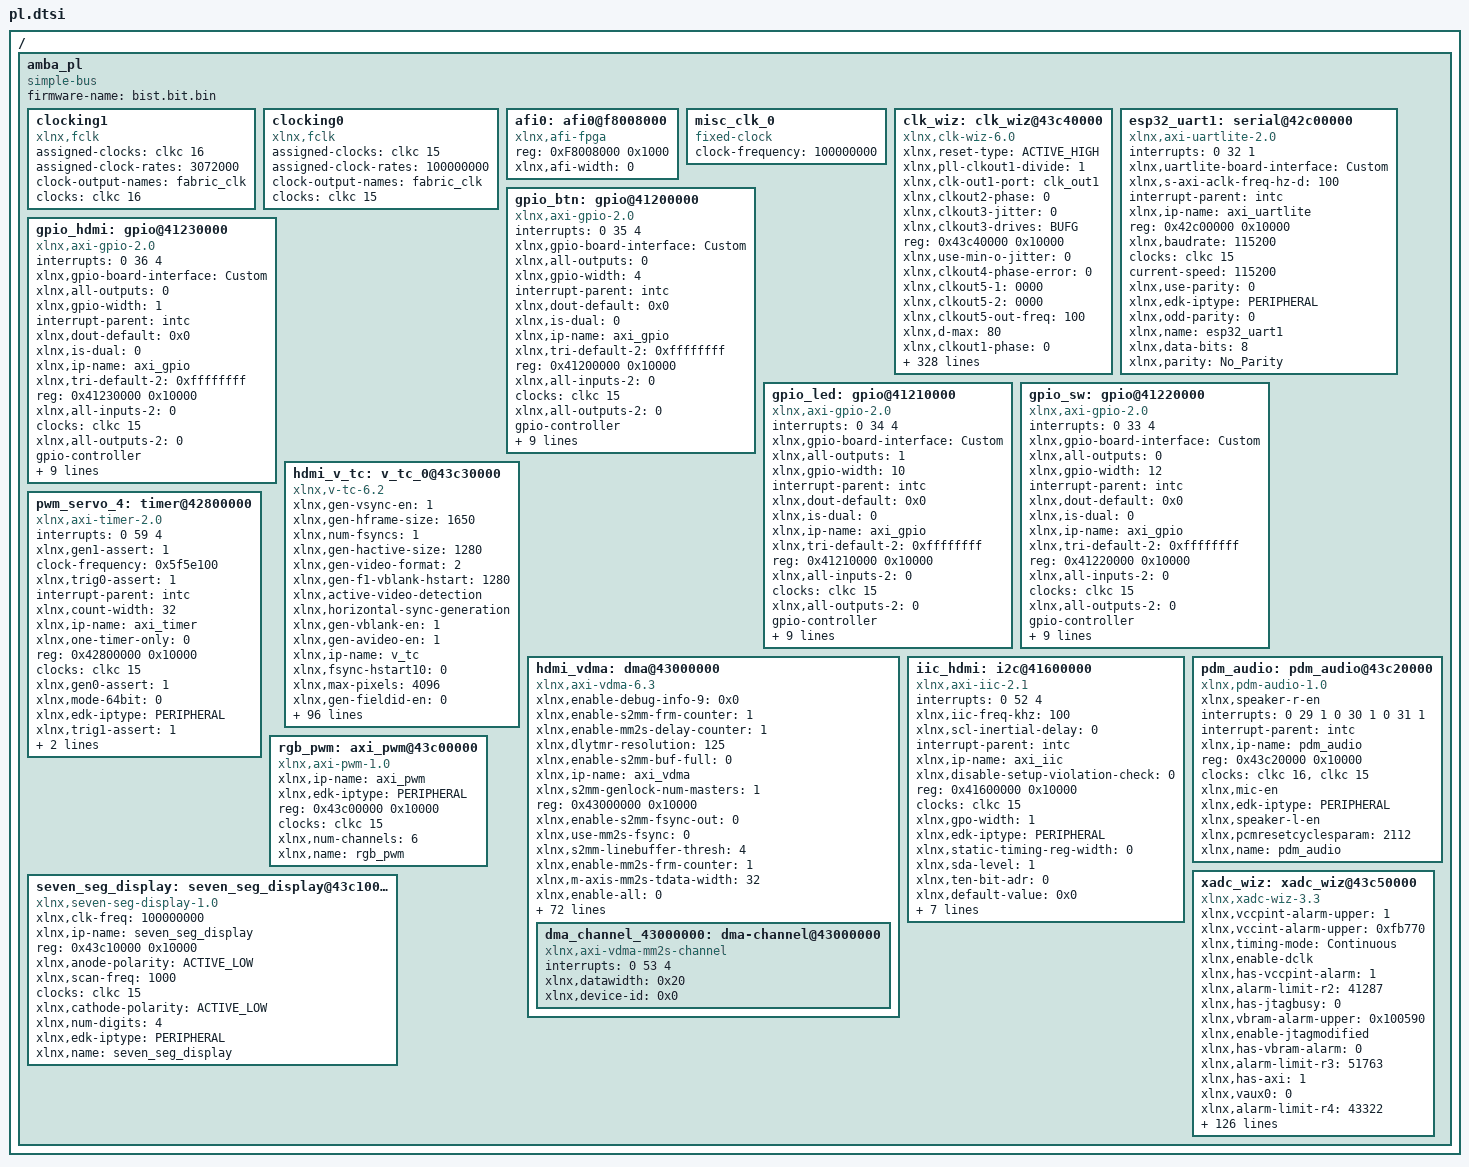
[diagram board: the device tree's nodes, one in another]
/ {
	amba_pl: amba_pl {
		ranges;
		compatible = "simple-bus";
		#address-cells = <1>;
		#size-cells = <1>;
		firmware-name = "bist.bit.bin";
		clocking1: clocking1 {
			compatible = "xlnx,fclk";
			assigned-clocks = <&clkc 16>;
			assigned-clock-rates = <3072000>;
			#clock-cells = <0>;
			clock-output-names = "fabric_clk";
			clocks = <&clkc 16>;
		};
		clocking0: clocking0 {
			compatible = "xlnx,fclk";
			assigned-clocks = <&clkc 15>;
			assigned-clock-rates = <100000000>;
			#clock-cells = <0>;
			clock-output-names = "fabric_clk";
			clocks = <&clkc 15>;
		};
		afi0: afi0@f8008000 {
			status = "okay";
			compatible = "xlnx,afi-fpga";
			#address-cells = <1>;
			reg = <0xF8008000 0x1000>;
			#size-cells = <0>;
			xlnx,afi-width = <0>;
		};
		misc_clk_0: misc_clk_0 {
			compatible = "fixed-clock";
			clock-frequency = <100000000>;
			#clock-cells = <0>;
		};
		clk_wiz: clk_wiz@43c40000 {
			xlnx,reset-type = "ACTIVE_HIGH";
			xlnx,pll-clkout1-divide = <1>;
			xlnx,clk-out1-port = "clk_out1";
			xlnx,clkout2-phase = <0>;
			xlnx,clkout3-jitter = <0>;
			xlnx,clkout3-drives = "BUFG";
			reg = <0x43c40000 0x10000>;
			xlnx,use-min-o-jitter = <0>;
			xlnx,clkout4-phase-error = <0>;
			xlnx,clkout5-1 = <0000>;
			xlnx,clkout5-2 = <0000>;
			xlnx,clkout5-out-freq = <100>;
			xlnx,d-max = <80>;
			xlnx,clkout1-phase = <0>;
			xlnx,divide6-auto = <0x186a0>;
			xlnx,clkout1-jitter = <0x141f9c80>;
			xlnx,clkfb-in-n-port = "clkfb_in_n";
			xlnx,clkout2-requested-out-freq = <0x1620d350>;
			xlnx,use-locked = <1>;
			xlnx,pll-clkout5-duty-cycle = <0x7a120>;
			xlnx,mmcm-clkout3-use-fine-ps;
			xlnx,clkout1-drives = "BUFG";
			xlnx,input-clk-stopped-port = "input_clk_stopped";
			xlnx,clkout4-duty-cycle = <50>;
			xlnx,divide3-auto = <0x186a0>;
			xlnx,use-dyn-reconfig = <1>;
			xlnx,clkout3-actual-freq = <100>;
			xlnx,clkout6-requested-duty-cycle = <50>;
			xlnx,diff-clk-in1-board-interface = "Custom";
			xlnx,mmcm-clkout0-duty-cycle = <0x7a120>;
			xlnx,clkin2-jitter-ps = <100>;
			xlnx,clkout2-1 = <0000>;
			xlnx,in-freq-units = "Units_MHz";
			xlnx,clkout2-2 = <0000>;
			xlnx,feedback-source = "FDBK_AUTO";
			xlnx,clkout5-requested-out-freq = <100>;
			xlnx,name = "clk_wiz";
			xlnx,prim-in-freq = <100>;
			xlnx,mmcm-clkout5-divide = <1>;
			xlnx,clkout3-phase-error = <0>;
			xlnx,clk-in2-board-interface = "Custom";
			xlnx,clkin1-ui-jitter = <0x2710>;
			xlnx,use-inclk-switchover = <0>;
			clock-names = "s_axi_aclk" , "clk_in1";
			xlnx,clkout5-duty-cycle = <50>;
			xlnx,use-clkout4-bar = <0>;
			xlnx,mmcm-clkout1-duty-cycle = <0x7a120>;
			xlnx,mmcm-clkout2-use-fine-ps;
			xlnx,clkout2-out-freq = <0x1620d350>;
			xlnx,use-dyn-phase-shift = <0>;
			xlnx,mmcm-clkout3-divide = <1>;
			xlnx,clkout2-actual-freq = <100>;
			xlnx,o-min = <1>;
			xlnx,daddr-port = "daddr";
			xlnx,precision = <1>;
			xlnx,mmcm-ref-jitter1 = <0x2710>;
			clock-output-names = "0x43c40000-clk_out1 0x43c40000-clk_out2";
			xlnx,mmcm-ref-jitter2 = <0x2710>;
			xlnx,pll-notes = "No , notes";
			xlnx,use-phase-alignment = <0>;
			xlnx,ref-clk-freq = <100>;
			xlnx,clkout7-requested-duty-cycle = <50>;
			xlnx,inclk-sum-row0 = "Input , Clock , Freq , (MHz) , Input , Jitter , (UI)";
			xlnx,inclk-sum-row1 = "__primary_________100.000____________0.010";
			xlnx,use-fast-simulation = <0>;
			xlnx,inclk-sum-row2 = "no_secondary_input_clock";
			xlnx,mmcm-clkout1-divide = <2>;
			xlnx,din-port = "din";
			xlnx,reset-board-interface = "Custom";
			xlnx,clkout6-duty-cycle = <50>;
			xlnx,clkout2-phase-error = <0x134092d8>;
			xlnx,clkout1-requested-duty-cycle = <50>;
			xlnx,vco-max = <1200>;
			xlnx,use-freq-synth = <1>;
			xlnx,primtype-sel = "AUTO";
			xlnx,mmcm-clkout2-duty-cycle = <0x7a120>;
			xlnx,clkout5-used = <0>;
			xlnx,d-min = <1>;
			xlnx,pll-clkfbout-mult = <1>;
			xlnx,mmcm-clkout4-cascade;
			xlnx,use-clkout1-bar = <0>;
			xlnx,clk-out6-port = "clk_out6";
			xlnx,clkout2-sequence-number = <1>;
			xlnx,clk-valid-port = "CLK_VALID";
			xlnx,clkout2-used = <1>;
			xlnx,clkout4-sequence-number = <1>;
			xlnx,psincdec-port = "psincdec";
			xlnx,mmcm-clkout1-use-fine-ps;
			xlnx,clk-out3-port = "clk_out3";
			xlnx,clkout6-sequence-number = <1>;
			xlnx,platform = "UNKNOWN";
			xlnx,mmcm-clkout6-phase = <0>;
			xlnx,clkout1-actual-freq = <0x1620d350>;
			xlnx,clkout6-out-freq = <100>;
			xlnx,nr-outputs = <2>;
			xlnx,mmcm-clkin2-period = <10>;
			xlnx,prim-in-jitter = <0x2710>;
			xlnx,mmcm-clkfbout-mult-f = <0x2367b88>;
			status = "okay";
			xlnx,clkout6-1 = <0000>;
			xlnx,clkout6-2 = <0000>;
			xlnx,clkout7-duty-cycle = <50>;
			xlnx,outclk-sum-row1 = "clk_out1__74.25000______0.000______50.0______337.616____322.999";
			xlnx,outclk-sum-row2 = "clk_out2__371.25000______0.000______50.0______258.703____322.999";
			xlnx,jitter-sel = "No_Jitter";
			xlnx,outclk-sum-row3 = "no_CLK_OUT3_output";
			xlnx,mmcm-clkout5-phase = <0>;
			xlnx,mmcm-clkout3-duty-cycle = <0x7a120>;
			xlnx,outclk-sum-row4 = "no_CLK_OUT4_output";
			xlnx,clkfb-in-p-port = "clkfb_in_p";
			xlnx,outclk-sum-row5 = "no_CLK_OUT5_output";
			xlnx,outclk-sum-row6 = "no_CLK_OUT6_output";
			xlnx,outclk-sum-row7 = "no_CLK_OUT7_output";
			xlnx,clkout1-phase-error = <0x134092d8>;
			xlnx,divide5-auto = <0x186a0>;
			xlnx,pll-bandwidth = "OPTIMIZED";
			xlnx,psdone-port = "psdone";
			xlnx,clkout3-1 = <0000>;
			xlnx,edk-iptype = "PERIPHERAL";
			xlnx,clkout3-2 = <0000>;
			xlnx,clkout3-requested-out-freq = <100>;
			xlnx,pll-clkout4-divide = <1>;
			xlnx,pll-clkfbout-phase = <0>;
			xlnx,divide2-auto = <0x30d40>;
			xlnx,override-mmcm = <0>;
			xlnx,clkout6-jitter = <0>;
			xlnx,ss-mode = "CENTER_HIGH";
			xlnx,mmcm-notes = "None";
			xlnx,clkout6-drives = "BUFG";
			xlnx,mmcm-clkfbout-use-fine-ps;
			xlnx,mmcm-clkout0-use-fine-ps;
			xlnx,ss-mod-period = <4000>;
			xlnx,mmcm-clkout4-phase = <0>;
			xlnx,clkout2-requested-duty-cycle = <50>;
			xlnx,clkout0-actual-freq = <0x46cf710>;
			xlnx,divclk = <0000>;
			xlnx,primary-port = "clk_in1";
			xlnx,mmcm-compensation = "ZHOLD";
			xlnx,clkout6-requested-out-freq = <100>;
			xlnx,clkout0-1 = <0000>;
			xlnx,clkout0-2 = <0000>;
			xlnx,clkout2-requested-phase = <0>;
			xlnx,relative-inclk = "REL_PRIMARY";
			xlnx,pll-clkout2-divide = <1>;
			xlnx,clkout4-requested-phase = <0>;
			xlnx,enable-user-clock0 = <0>;
			xlnx,filter-1 = <0000>;
			xlnx,mmcm-clkout4-duty-cycle = <0x7a120>;
			xlnx,clkout3-out-freq = <100>;
			xlnx,clkout4-jitter = <0>;
			xlnx,clkout6-requested-phase = <0>;
			xlnx,clkoutphy-requested-freq = <600>;
			xlnx,enable-user-clock1 = <0>;
			xlnx,filter-2 = <0000>;
			xlnx,ss-mod-freq = <250>;
			xlnx,in-jitter-units = "Units_UI";
			xlnx,mmcm-divclk-divide = <5>;
			xlnx,enable-user-clock2 = <0>;
			xlnx,enable-user-clock3 = <0>;
			xlnx,lock-1 = <0000>;
			xlnx,clkout4-drives = "BUFG";
			xlnx,lock-2 = <0000>;
			xlnx,den-port = "den";
			xlnx,lock-3 = <0000>;
			xlnx,use-safe-clock-startup = <0>;
			xlnx,mmcm-clkout3-phase = <0>;
			xlnx,dwe-port = "dwe";
			xlnx,clkfb-out-n-port = "clkfb_out_n";
			xlnx,use-max-i-jitter = <0>;
			xlnx,drdy-port = "drdy";
			xlnx,vco-min = <600>;
			xlnx,pll-clkout0-divide = <1>;
			xlnx,clkin1-jitter-ps = <100>;
			xlnx,clk-in-sel-port = "clk_in_sel";
			xlnx,use-freeze = <0>;
			xlnx,clkout2-jitter = <0xf6b7e97>;
			xlnx,enable-pll0 = <0>;
			xlnx,enable-pll1 = <0>;
			xlnx,clkout2-drives = "BUFG";
			xlnx,use-inclk-stopped = <0>;
			xlnx,use-clkout3-bar = <0>;
			xlnx,use-clk-valid = <0>;
			xlnx,mmcm-clkout2-phase = <0>;
			compatible = "xlnx,clk-wiz-6.0" , "xlnx,versal-clk-wizard";
			xlnx,reset-port = "reset";
			xlnx,mmcm-clkout5-duty-cycle = <0x7a120>;
			xlnx,mmcm-clkout0-divide-f = <10>;
			xlnx,pll-clkout0-duty-cycle = <0x7a120>;
			xlnx,speed-grade = <1>;
			xlnx,diff-clk-in2-board-interface = "Custom";
			xlnx,clkout3-requested-duty-cycle = <50>;
			xlnx,use-status = <0>;
			xlnx,prim-source = "Single_ended_clock_capable_pin";
			xlnx,clkout7-used = <0>;
			xlnx,use-clkfb-stopped = <0>;
			xlnx,mmcm-clkout1-phase = <0>;
			xlnx,mmcm-clkout6-divide = <1>;
			xlnx,clkout7-out-freq = <100>;
			xlnx,prim-in-timeperiod = <10>;
			xlnx,clkout4-used = <0>;
			xlnx,pll-clkin-period = <1>;
			xlnx,clk-out5-port = "clk_out5";
			xlnx,psclk-port = "psclk";
			xlnx,primitive = "MMCM";
			xlnx,clkout1-used;
			xlnx,reset-low = <0>;
			xlnx,clk-in1-board-interface = "Custom";
			xlnx,clk-out2-port = "clk_out2";
			xlnx,power-down-port = "power_down";
			xlnx,clkout7-phase-error = <0>;
			xlnx,mmcm-clkout6-duty-cycle = <0x7a120>;
			xlnx,mmcm-clkout4-divide = <1>;
			xlnx,mmcm-clkfbout-phase = <0>;
			xlnx,mmcm-clkout0-phase = <0>;
			xlnx,pll-clkout1-duty-cycle = <0x7a120>;
			xlnx,user-clk-freq0 = <100>;
			xlnx,user-clk-freq1 = <100>;
			xlnx,pll-clkout5-phase = <0>;
			xlnx,user-clk-freq2 = <100>;
			xlnx,secondary-in-jitter = <0x2710>;
			xlnx,user-clk-freq3 = <100>;
			xlnx,use-clock-sequencing = <0>;
			xlnx,secondary-source = "Single_ended_clock_capable_pin";
			xlnx,cddcdone-port = "cddcdone";
			xlnx,clkout7-phase = <0>;
			xlnx,psen-port = "psen";
			xlnx,mmcm-clkout6-use-fine-ps;
			xlnx,dclk-port = "dclk";
			xlnx,m-max = <64>;
			xlnx,outclk-sum-row0a = "Output , Output , Phase , Duty , Cycle , Pk-to-Pk , Phase";
			xlnx,clkout1-requested-out-freq = <0x46cf710>;
			xlnx,clkout6-actual-freq = <100>;
			xlnx,divide7-auto = <0x186a0>;
			xlnx,outclk-sum-row0b = "Clock , Freq , (MHz) , (degrees) , (%) , Jitter , (ps) , Error , (ps)";
			xlnx,clkout4-1 = <0000>;
			xlnx,locked-port = "locked";
			xlnx,clkin2-ui-jitter = <0x2710>;
			xlnx,clkout4-2 = <0000>;
			xlnx,enable-clock-monitor = <0>;
			xlnx,mmcm-clkout2-divide = <1>;
			xlnx,ss-mod-time = <0xfa0>;
			xlnx,auto-primitive = "MMCM";
			xlnx,divide4-auto = <0x186a0>;
			xlnx,pll-clkout4-phase = <0>;
			xlnx,use-power-down = <0>;
			xlnx,mmcm-startup-wait;
			xlnx,divide1-auto = <1>;
			xlnx,clkout4-requested-duty-cycle = <50>;
			xlnx,clkout4-requested-out-freq = <100>;
			xlnx,optimize-clocking-structure-en = <0>;
			xlnx,clkout4-out-freq = <100>;
			xlnx,clkout6-phase = <0>;
			xlnx,num-out-clks = <2>;
			xlnx,ip-name = "clk_wiz";
			xlnx,pll-clkout2-duty-cycle = <0x7a120>;
			xlnx,clkout1-1 = <0000>;
			xlnx,clkout1-2 = <0000>;
			xlnx,clkout1-duty-cycle = <50>;
			xlnx,pll-divclk-divide = <1>;
			xlnx,clkout6-phase-error = <0>;
			xlnx,dout-port = "dout";
			xlnx,clkout1-sequence-number = <1>;
			xlnx,pll-clkout3-phase = <0>;
			xlnx,cddcreq-port = "cddcreq";
			xlnx,clkout7-requested-out-freq = <100>;
			xlnx,use-spread-spectrum = <0>;
			xlnx,clkout3-sequence-number = <1>;
			xlnx,clkout5-sequence-number = <1>;
			xlnx,summary-strings = "empty";
			xlnx,pll-compensation = "SYSTEM_SYNCHRONOUS";
			xlnx,clkout5-phase = <0>;
			xlnx,clkout7-sequence-number = <1>;
			xlnx,status-port = "STATUS";
			xlnx,clkfb-out-p-port = "clkfb_out_p";
			xlnx,mmcm-clkout5-use-fine-ps;
			xlnx,clkfb-in-port = "clkfb_in";
			xlnx,clkout5-actual-freq = <100>;
			xlnx,input-mode = "frequency";
			xlnx,interface-selection = <1>;
			xlnx,mmcm-bandwidth = "OPTIMIZED";
			xlnx,calc-done = "empty";
			xlnx,use-board-flow;
			xlnx,pll-clkout2-phase = <0>;
			xlnx,has-cddc = <0>;
			xlnx,power-reg = <0000>;
			xlnx,mmcm-clkin1-period = <10>;
			xlnx,pll-clkout3-duty-cycle = <0x7a120>;
			xlnx,clkout2-duty-cycle = <50>;
			xlnx,clkout4-phase = <0>;
			xlnx,pll-clkout5-divide = <1>;
			xlnx,clkout7-jitter = <0>;
			clocks = <&clkc 15>, <&misc_clk_0>;
			xlnx,clkout1-out-freq = <0x46cf710>;
			xlnx,clkout7-drives = "BUFG";
			xlnx,clkout5-phase-error = <0>;
			xlnx,pll-clkout1-phase = <0>;
			xlnx,clkout5-requested-duty-cycle = <50>;
			xlnx,clkfb-in-signaling = "SINGLE";
			xlnx,enable-clkoutphy = <0>;
			xlnx,use-clkout2-bar = <0>;
			xlnx,secondary-port = "clk_in2";
			xlnx,clkout3-phase = <0>;
			xlnx,pll-clkout3-divide = <1>;
			xlnx,use-reset = <1>;
			xlnx,override-pll = <0>;
			xlnx,clkoutphy-mode = "VCO";
			xlnx,mmcm-clkout4-use-fine-ps;
			xlnx,clkout5-jitter = <0>;
			xlnx,clkout6-used = <0>;
			xlnx,m-min = <2>;
			xlnx,mmcm-clock-hold;
			xlnx,clkfb-stopped-port = "clkfb_stopped";
			xlnx,clk-out7-port = "clk_out7";
			xlnx,clkout1-requested-phase = <0>;
			xlnx,clkout4-actual-freq = <100>;
			xlnx,pll-clk-feedback = "CLKFBOUT";
			xlnx,phaseshift-mode = "WAVEFORM";
			xlnx,clkfb-out-port = "clkfb_out";
			xlnx,clkout5-drives = "BUFG";
			xlnx,o-max = <128>;
			xlnx,clkout3-requested-phase = <0>;
			xlnx,jitter-options = "UI";
			xlnx,secondary-in-timeperiod = <10>;
			xlnx,pll-clkout4-duty-cycle = <0x7a120>;
			xlnx,clkout3-used = <0>;
			xlnx,clkout5-requested-phase = <0>;
			xlnx,pll-clkout0-phase = <0>;
			xlnx,clk-out4-port = "clk_out4";
			xlnx,clkout3-duty-cycle = <50>;
			xlnx,clkout7-requested-phase = <0>;
			xlnx,secondary-in-freq = <100>;
			xlnx,use-min-power = <0>;
			xlnx,clkfbout-1 = <0000>;
			#clock-cells = <1>;
			xlnx,pll-ref-jitter = <0x2710>;
			xlnx,clkfbout-2 = <0000>;
			xlnx,component-name = "system_clk_wiz_0";
		};
		esp32_uart1: serial@42c00000 {
			interrupts = < 0 32 1 >;
			compatible = "xlnx,axi-uartlite-2.0" , "xlnx,xps-uartlite-1.00.a";
			xlnx,uartlite-board-interface = "Custom";
			xlnx,s-axi-aclk-freq-hz-d = <100>;
			interrupt-parent = <&intc>;
			xlnx,ip-name = "axi_uartlite";
			reg = <0x42c00000 0x10000>;
			xlnx,baudrate = <115200>;
			clocks = <&clkc 15>;
			current-speed = <115200>;
			xlnx,use-parity = <0>;
			xlnx,edk-iptype = "PERIPHERAL";
			xlnx,odd-parity = <0>;
			status = "okay";
			clock-names = "s_axi_aclk";
			interrupt-names = "interrupt";
			xlnx,name = "esp32_uart1";
			xlnx,data-bits = <8>;
			xlnx,parity = "No_Parity";
		};
		gpio_btn: gpio@41200000 {
			#interrupt-cells = <2>;
			interrupts = < 0 35 4 >;
			xlnx,gpio-board-interface = "Custom";
			compatible = "xlnx,axi-gpio-2.0" , "xlnx,xps-gpio-1.00.a";
			xlnx,all-outputs = <0>;
			#gpio-cells = <2>;
			xlnx,gpio-width = <4>;
			interrupt-parent = <&intc>;
			xlnx,dout-default = <0x0>;
			xlnx,is-dual = <0>;
			xlnx,ip-name = "axi_gpio";
			xlnx,tri-default-2 = <0xffffffff>;
			reg = <0x41200000 0x10000>;
			xlnx,all-inputs-2 = <0>;
			clocks = <&clkc 15>;
			xlnx,all-outputs-2 = <0>;
			gpio-controller;
			xlnx,interrupt-present = <1>;
			xlnx,gpio2-board-interface = "Custom";
			xlnx,edk-iptype = "PERIPHERAL";
			xlnx,dout-default-2 = <0x0>;
			status = "okay";
			xlnx,gpio2-width = <32>;
			clock-names = "s_axi_aclk";
			interrupt-controller;
			interrupt-names = "ip2intc_irpt";
			xlnx,tri-default = <0xffffffff>;
			xlnx,name = "gpio_btn";
			xlnx,all-inputs = <1>;
		};
		gpio_hdmi: gpio@41230000 {
			#interrupt-cells = <2>;
			interrupts = < 0 36 4 >;
			xlnx,gpio-board-interface = "Custom";
			compatible = "xlnx,axi-gpio-2.0" , "xlnx,xps-gpio-1.00.a";
			xlnx,all-outputs = <0>;
			#gpio-cells = <2>;
			xlnx,gpio-width = <1>;
			interrupt-parent = <&intc>;
			xlnx,dout-default = <0x0>;
			xlnx,is-dual = <0>;
			xlnx,ip-name = "axi_gpio";
			xlnx,tri-default-2 = <0xffffffff>;
			reg = <0x41230000 0x10000>;
			xlnx,all-inputs-2 = <0>;
			clocks = <&clkc 15>;
			xlnx,all-outputs-2 = <0>;
			gpio-controller;
			xlnx,interrupt-present = <1>;
			xlnx,gpio2-board-interface = "Custom";
			xlnx,edk-iptype = "PERIPHERAL";
			xlnx,dout-default-2 = <0x0>;
			status = "okay";
			xlnx,gpio2-width = <32>;
			clock-names = "s_axi_aclk";
			interrupt-controller;
			interrupt-names = "ip2intc_irpt";
			xlnx,tri-default = <0xffffffff>;
			xlnx,name = "gpio_hdmi";
			xlnx,all-inputs = <1>;
		};
		gpio_led: gpio@41210000 {
			#interrupt-cells = <2>;
			interrupts = < 0 34 4 >;
			xlnx,gpio-board-interface = "Custom";
			compatible = "xlnx,axi-gpio-2.0" , "xlnx,xps-gpio-1.00.a";
			xlnx,all-outputs = <1>;
			#gpio-cells = <2>;
			xlnx,gpio-width = <10>;
			interrupt-parent = <&intc>;
			xlnx,dout-default = <0x0>;
			xlnx,is-dual = <0>;
			xlnx,ip-name = "axi_gpio";
			xlnx,tri-default-2 = <0xffffffff>;
			reg = <0x41210000 0x10000>;
			xlnx,all-inputs-2 = <0>;
			clocks = <&clkc 15>;
			xlnx,all-outputs-2 = <0>;
			gpio-controller;
			xlnx,interrupt-present = <1>;
			xlnx,gpio2-board-interface = "Custom";
			xlnx,edk-iptype = "PERIPHERAL";
			xlnx,dout-default-2 = <0x0>;
			status = "okay";
			xlnx,gpio2-width = <32>;
			clock-names = "s_axi_aclk";
			interrupt-controller;
			interrupt-names = "ip2intc_irpt";
			xlnx,tri-default = <0xffffffff>;
			xlnx,name = "gpio_led";
			xlnx,all-inputs = <0>;
		};
		gpio_sw: gpio@41220000 {
			#interrupt-cells = <2>;
			interrupts = < 0 33 4 >;
			xlnx,gpio-board-interface = "Custom";
			compatible = "xlnx,axi-gpio-2.0" , "xlnx,xps-gpio-1.00.a";
			xlnx,all-outputs = <0>;
			#gpio-cells = <2>;
			xlnx,gpio-width = <12>;
			interrupt-parent = <&intc>;
			xlnx,dout-default = <0x0>;
			xlnx,is-dual = <0>;
			xlnx,ip-name = "axi_gpio";
			xlnx,tri-default-2 = <0xffffffff>;
			reg = <0x41220000 0x10000>;
			xlnx,all-inputs-2 = <0>;
			clocks = <&clkc 15>;
			xlnx,all-outputs-2 = <0>;
			gpio-controller;
			xlnx,interrupt-present = <1>;
			xlnx,gpio2-board-interface = "Custom";
			xlnx,edk-iptype = "PERIPHERAL";
			xlnx,dout-default-2 = <0x0>;
			status = "okay";
			xlnx,gpio2-width = <32>;
			clock-names = "s_axi_aclk";
			interrupt-controller;
			interrupt-names = "ip2intc_irpt";
			xlnx,tri-default = <0xffffffff>;
			xlnx,name = "gpio_sw";
			xlnx,all-inputs = <1>;
		};
		hdmi_v_tc: v_tc_0@43c30000 {
			xlnx,gen-vsync-en = <1>;
			xlnx,gen-hframe-size = <1650>;
			xlnx,num-fsyncs = <1>;
			xlnx,gen-hactive-size = <1280>;
			xlnx,gen-video-format = <2>;
			xlnx,gen-f1-vblank-hstart = <1280>;
			xlnx,active-video-detection;
			xlnx,horizontal-sync-generation;
			xlnx,gen-vblank-en = <1>;
			xlnx,gen-avideo-en = <1>;
			xlnx,ip-name = "v_tc";
			xlnx,fsync-hstart10 = <0>;
			xlnx,max-pixels = <4096>;
			xlnx,gen-fieldid-en = <0>;
			reg = <0x43c30000 0x10000>;
			xlnx,det-vblank-en = <1>;
			xlnx,fsync-hstart11 = <0>;
			xlnx,fsync-hstart12 = <0>;
			xlnx,gen-interlaced = <0>;
			xlnx,det-avideo-en = <1>;
			xlnx,fsync-hstart13 = <0>;
			xlnx,fsync-hstart14 = <0>;
			xlnx,gen-f0-vblank-hend = <1280>;
			xlnx,fsync-hstart15 = <0>;
			xlnx,det-hsync-en = <1>;
			interrupt-names = "irq";
			xlnx,enable-generation;
			xlnx,gen-avideo-polarity = <1>;
			xlnx,max-lines-per-frame = <4096>;
			xlnx,has-axi4-lite = <1>;
			compatible = "xlnx,v-tc-6.2" , "xlnx,v-tc-6.1" , "xlnx,bridge-v-tc-6.1";
			xlnx,max-clocks-per-line = <4096>;
			xlnx,gen-f0-vframe-size = <750>;
			xlnx,gen-f0-vblank-hstart = <1280>;
			interrupt-parent = <&intc>;
			xlnx,max-lines = <4096>;
			xlnx,gen-f0-vsync-vstart = <724>;
			xlnx,horizontal-blank-generation;
			xlnx,gen-hsync-end = <1430>;
			xlnx,gen-f0-vsync-hstart = <1280>;
			xlnx,gen-f1-vsync-hend = <1280>;
			xlnx,vertical-blank-detection;
			xlnx,gen-vsync-polarity = <1>;
			xlnx,fsync-vstart0 = <0>;
			xlnx,gen-hsync-polarity = <1>;
			xlnx,fsync-vstart1 = <0>;
			status = "okay";
			xlnx,fsync-vstart2 = <0>;
			xlnx,gen-hsync-start = <1390>;
			xlnx,gen-f0-vsync-vend = <729>;
			xlnx,fsync-vstart3 = <0>;
			xlnx,vertical-sync-detection;
			xlnx,frame-syncs = <1>;
			xlnx,fsync-vstart4 = <0>;
			xlnx,gen-vactive-size = <720>;
			xlnx,name = "hdmi_v_tc";
			xlnx,fsync-vstart5 = <0>;
			interrupts = < 0 54 4 >;
			xlnx,gen-achroma-en = <0>;
			xlnx,fsync-vstart6 = <0>;
			xlnx,det-fieldid-en = <0>;
			xlnx,fsync-vstart7 = <0>;
			xlnx,gen-hsync-en = <1>;
			xlnx,fsync-vstart8 = <0>;
			xlnx,fsync-vstart10 = <0>;
			xlnx,fsync-vstart9 = <0>;
			xlnx,fsync-vstart11 = <0>;
			xlnx,arbitrary-res-en = <0>;
			xlnx,fsync-vstart12 = <0>;
			xlnx,fsync-vstart13 = <0>;
			clocks = <&clk_wiz 0>, <&clkc 15>;
			xlnx,fsync-vstart14 = <0>;
			xlnx,fsync-vstart15 = <0>;
			xlnx,gen-cparity = <0>;
			xlnx,edk-iptype = "PERIPHERAL";
			xlnx,vertical-sync-generation;
			xlnx,gen-f1-vblank-hend = <1280>;
			xlnx,det-vsync-en = <1>;
			xlnx,gen-vblank-polarity = <1>;
			xlnx,fsync-hstart0 = <0>;
			clock-names = "clk" , "s_axi_aclk";
			xlnx,interlace-en = <0>;
			xlnx,gen-auto-switch = <0>;
			xlnx,fsync-hstart1 = <0>;
			xlnx,fsync-hstart2 = <0>;
			xlnx,active-video-generation;
			xlnx,fsync-hstart3 = <0>;
			xlnx,fsync-hstart4 = <0>;
			xlnx,horizontal-blank-detection;
			xlnx,fsync-hstart5 = <0>;
			xlnx,gen-f1-vframe-size = <750>;
			xlnx,fsync-hstart6 = <0>;
			xlnx,fsync-hstart7 = <0>;
			xlnx,fsync-hstart8 = <0>;
			xlnx,gen-hblank-en = <1>;
			xlnx,fsync-hstart9 = <0>;
			xlnx,horizontal-sync-detection;
			xlnx,gen-f1-vsync-vend = <729>;
			xlnx,detect-en = <0>;
			xlnx,det-hblank-en = <1>;
			xlnx,vid-ppc = <4>;
			xlnx,has-intc-if = <0>;
			xlnx,generate-en = <1>;
			xlnx,gen-achroma-polarity = <1>;
			xlnx,sync-en = <0>;
			xlnx,det-achroma-en = <0>;
			xlnx,generator;
			xlnx,gen-f1-vsync-vstart = <724>;
			xlnx,vertical-blank-generation;
			xlnx,gen-hblank-polarity = <1>;
			xlnx,video-mode = "720p";
			xlnx,gen-fieldid-polarity = <1>;
			xlnx,gen-f1-vsync-hstart = <1280>;
			xlnx,gen-f0-vsync-hend = <1280>;
		};
		hdmi_vdma: dma@43000000 {
			xlnx,enable-debug-info-9 = <0x0>;
			xlnx,enable-s2mm-frm-counter = <1>;
			xlnx,enable-mm2s-delay-counter = <1>;
			xlnx,dlytmr-resolution = <125>;
			xlnx,enable-s2mm-buf-full = <0>;
			xlnx,ip-name = "axi_vdma";
			xlnx,s2mm-genlock-num-masters = <1>;
			reg = <0x43000000 0x10000>;
			xlnx,enable-s2mm-fsync-out = <0>;
			xlnx,use-mm2s-fsync = <0>;
			xlnx,s2mm-linebuffer-thresh = <4>;
			xlnx,enable-mm2s-frm-counter = <1>;
			xlnx,m-axis-mm2s-tdata-width = <32>;
			xlnx,enable-all = <0>;
			xlnx,dynamic-resolution = <1>;
			xlnx,enable-s2mm-rst-out = <0>;
			interrupt-names = "mm2s_introut";
			xlnx,s2mm-sof-enable = <0x1>;
			xlnx,mm2s-genlock-num-masters = <1>;
			xlnx,enable-mm2s-fsync-out = <0>;
			xlnx,mm2s-linebuffer-thresh = <4>;
			compatible = "xlnx,axi-vdma-6.3" , "xlnx,axi-vdma-1.00.a";
			xlnx,enable-tstvec = <0>;
			interrupt-parent = <&intc>;
			xlnx,s2mm-max-burst-length = <8>;
			xlnx,enable-mm2s-rst-out = <0>;
			xlnx,mm2s-sof-enable = <1>;
			xlnx,include-s2mm-dre = <0x0>;
			xlnx,enable-s2mm-frmstr-reg = <0>;
			xlnx,m-axi-s2mm-data-width = <64>;
			xlnx,enable-s2mm-sts-reg = <0>;
			xlnx,mm2s-max-burst-length = <16>;
			status = "okay";
			xlnx,include-mm2s-dre = <0x0>;
			xlnx,name = "hdmi_vdma";
			xlnx,enable-mm2s-frmstr-reg = <0>;
			interrupts = < 0 53 4 >;
			xlnx,m-axi-mm2s-data-width = <64>;
			xlnx,flush-on-fsync = <0x1>;
			xlnx,include-s2mm-sf = <1>;
			xlnx,single-interface = <0>;
			xlnx,s2mm-linebuffer-depth = <0x200>;
			xlnx,include-s2mm = <0x0>;
			xlnx,addr-width = <32>;
			clocks = <&clkc 15>, <&clkc 15>, <&clkc 15>;
			xlnx,s-axis-s2mm-tdata-width = <32>;
			xlnx,enable-debug-info-10 = <0>;
			xlnx,addrwidth = <0x20>;
			xlnx,enable-debug-info-11 = <0>;
			xlnx,edk-iptype = "PERIPHERAL";
			xlnx,enable-debug-info-12 = <0>;
			xlnx,use-fsync = <1>;
			xlnx,s2mm-genlock-repeat-en = <1>;
			xlnx,enable-debug-info-13 = <0x0>;
			xlnx,enable-vert-flip = <0x0>;
			xlnx,include-mm2s-sf = <0>;
			xlnx,enable-debug-info-14 = <0x1>;
			xlnx,include-internal-genlock = <0x1>;
			clock-names = "s_axi_lite_aclk" , "m_axi_mm2s_aclk" , "m_axis_mm2s_aclk";
			xlnx,enable-debug-info-15 = <0x1>;
			xlnx,mm2s-linebuffer-depth = <0x800>;
			xlnx,include-mm2s = <0x1>;
			xlnx,s2mm-genlock-mode = <0x0>;
			xlnx,flush-fsync = <0x1>;
			xlnx,select-xpm = <0>;
			xlnx,s2mm-data-width = <0x40>;
			xlnx,num-fstores = <0x1>;
			xlnx,enable-s2mm-param-updt = <0>;
			xlnx,enable-vidparam-reads = <0x1>;
			xlnx,mm2s-genlock-repeat-en = <0>;
			xlnx,prmry-is-aclk-async = <0>;
			xlnx,s2mm-tdata-width = <0x20>;
			#dma-cells = <1>;
			xlnx,enable-vidprmtr-reads = <1>;
			xlnx,mm2s-genlock-mode = <0x0>;
			xlnx,enable-debug-info-0 = <0>;
			xlnx,enable-debug-all = <0x0>;
			xlnx,enable-debug-info-1 = <0x0>;
			xlnx,mm2s-data-width = <0x40>;
			xlnx,enable-debug-info-2 = <0>;
			xlnx,enable-mm2s-param-updt = <0>;
			xlnx,enable-debug-info-3 = <0>;
			xlnx,enable-s2mm-delay-counter = <1>;
			xlnx,enable-debug-info-4 = <0>;
			xlnx,enable-debug-info-5 = <0x0>;
			xlnx,mm2s-tdata-width = <0x20>;
			xlnx,enable-debug-info-6 = <0x1>;
			xlnx,enable-debug-info-7 = <0x1>;
			xlnx,use-s2mm-fsync = <2>;
			xlnx,enable-debug-info-8 = <0>;
			xlnx,enable-mm2s-buf-empty = <0>;
			dma_channel_43000000: dma-channel@43000000 {
				interrupts = < 0 53 4 >;
				xlnx,datawidth = <0x20>;
				xlnx,device-id = <0x0>;
				compatible = "xlnx,axi-vdma-mm2s-channel";
			};
		};
		iic_hdmi: i2c@41600000 {
			interrupts = < 0 52 4 >;
			xlnx,iic-freq-khz = <100>;
			compatible = "xlnx,axi-iic-2.1" , "xlnx,xps-iic-2.00.a";
			xlnx,scl-inertial-delay = <0>;
			interrupt-parent = <&intc>;
			xlnx,ip-name = "axi_iic";
			xlnx,disable-setup-violation-check = <0>;
			reg = <0x41600000 0x10000>;
			clocks = <&clkc 15>;
			xlnx,gpo-width = <1>;
			xlnx,edk-iptype = "PERIPHERAL";
			xlnx,static-timing-reg-width = <0>;
			xlnx,sda-level = <1>;
			status = "okay";
			clock-names = "s_axi_aclk";
			xlnx,ten-bit-adr = <0>;
			xlnx,default-value = <0x0>;
			interrupt-names = "iic2intc_irpt";
			xlnx,iic-board-interface = "Custom";
			xlnx,timing-reg-width = <32>;
			xlnx,iic-freq = <100000>;
			xlnx,smbus-pmbus-host = <0>;
			xlnx,name = "iic_hdmi";
			xlnx,axi-aclk-freq-mhz = <100>;
			xlnx,sda-inertial-delay = <0>;
		};
		pdm_audio: pdm_audio@43c20000 {
			compatible = "xlnx,pdm-audio-1.0";
			xlnx,speaker-r-en;
			interrupts = < 0 29 1 0 30 1 0 31 1 >;
			interrupt-parent = <&intc>;
			xlnx,ip-name = "pdm_audio";
			reg = <0x43c20000 0x10000>;
			clocks = <&clkc 16>, <&clkc 15>;
			xlnx,mic-en;
			xlnx,edk-iptype = "PERIPHERAL";
			xlnx,speaker-l-en;
			status = "okay";
			clock-names = "pdm_mclk" , "s_axi_aclk";
			xlnx,pcmresetcyclesparam = <2112>;
			interrupt-names = "spkLIntr" , "spkRIntr" , "micIntr";
			xlnx,name = "pdm_audio";
		};
		pwm_servo_4: timer@42800000 {
			interrupts = < 0 59 4 >;
			compatible = "xlnx,axi-timer-2.0" , "xlnx,xps-timer-1.00.a";
			xlnx,gen1-assert = <1>;
			clock-frequency = <0x5f5e100>;
			xlnx,trig0-assert = <1>;
			interrupt-parent = <&intc>;
			xlnx,count-width = <32>;
			xlnx,ip-name = "axi_timer";
			xlnx,one-timer-only = <0>;
			reg = <0x42800000 0x10000>;
			clocks = <&clkc 15>;
			xlnx,gen0-assert = <1>;
			xlnx,mode-64bit = <0>;
			xlnx,edk-iptype = "PERIPHERAL";
			status = "okay";
			xlnx,trig1-assert = <1>;
			clock-names = "s_axi_aclk";
			xlnx,enable-timer2 = <1>;
			interrupt-names = "interrupt";
			xlnx,name = "pwm_servo_4";
		};
		rgb_pwm: axi_pwm@43c00000 {
			compatible = "xlnx,axi-pwm-1.0";
			status = "okay";
			clock-names = "s_axi_aclk";
			xlnx,ip-name = "axi_pwm";
			xlnx,edk-iptype = "PERIPHERAL";
			reg = <0x43c00000 0x10000>;
			clocks = <&clkc 15>;
			xlnx,num-channels = <6>;
			xlnx,name = "rgb_pwm";
		};
		seven_seg_display: seven_seg_display@43c10000 {
			compatible = "xlnx,seven-seg-display-1.0";
			xlnx,clk-freq = <100000000>;
			xlnx,ip-name = "seven_seg_display";
			reg = <0x43c10000 0x10000>;
			xlnx,anode-polarity = "ACTIVE_LOW";
			xlnx,scan-freq = <1000>;
			clocks = <&clkc 15>;
			xlnx,cathode-polarity = "ACTIVE_LOW";
			xlnx,num-digits = <4>;
			xlnx,edk-iptype = "PERIPHERAL";
			status = "okay";
			clock-names = "s_axi_aclk";
			xlnx,name = "seven_seg_display";
		};
		xadc_wiz: xadc_wiz@43c50000 {
			xlnx,vccpint-alarm-upper = <1>;
			xlnx,vccint-alarm-upper = <0xfb770>;
			xlnx,timing-mode = "Continuous";
			xlnx,enable-dclk;
			xlnx,has-vccpint-alarm = <1>;
			xlnx,alarm-limit-r2 = <41287>;
			xlnx,has-jtagbusy = <0>;
			xlnx,vbram-alarm-upper = <0x100590>;
			xlnx,enable-jtagmodified;
			xlnx,has-vbram-alarm = <0>;
			xlnx,alarm-limit-r3 = <51763>;
			xlnx,has-axi = <1>;
			xlnx,vaux0 = <0>;
			xlnx,alarm-limit-r4 = <43322>;
			xlnx,has-busy = <1>;
			xlnx,ot-alarm;
			xlnx,enable-channel;
			xlnx,vaux1 = <0>;
			xlnx,has-vccaux-alarm = <1>;
			xlnx,alarm-limit-r5 = <21190>;
			xlnx,dclk-frequency = <100>;
			xlnx,vaux2 = <0>;
			xlnx,alarm-limit-r6 = <38229>;
			xlnx,vaux3 = <0>;
			xlnx,ip-name = "xadc_wiz";
			xlnx,alarm-limit-r7 = <44622>;
			xlnx,configuration-r0 = <0>;
			xlnx,has-drp = <0>;
			xlnx,vaux4 = <0>;
			xlnx,sim-file-rel-path = "./";
			reg = <0x43c50000 0x10000>;
			xlnx,alarm-limit-r8 = <22937>;
			xlnx,configuration-r1 = <12704>;
			xlnx,external-mux-channel = "VP_VN";
			xlnx,vccint-alarm;
			xlnx,temperature-alarm-trigger = <85>;
			xlnx,vaux5 = <0>;
			xlnx,alarm-limit-r9 = <20753>;
			xlnx,configuration-r2 = <1024>;
			xlnx,has-jtaglocked = <0>;
			xlnx,vaux6 = <0>;
			xlnx,vaux7 = <0>;
			xlnx,user-temp-alarm;
			xlnx,vaux8 = <0>;
			xlnx,vaux9 = <0>;
			xlnx,vaux10 = <0>;
			xlnx,has-vn = <1>;
			xlnx,has-vccpaux-alarm = <1>;
			xlnx,acquisition-time = <4>;
			xlnx,vaux11 = <0>;
			xlnx,has-temp-bus = <0>;
			xlnx,xadc-starup-selection = "single_channel";
			xlnx,enable-busy;
			xlnx,data-width = <32>;
			xlnx,vaux12 = <0>;
			xlnx,sim-file-sel = "Default";
			xlnx,has-vp = <1>;
			xlnx,ip-type = <0x0>;
			interrupt-names = "ip2intc_irpt";
			xlnx,temperature-alarm-ot-reset = <70>;
			xlnx,vaux13 = <0>;
			xlnx,enable-convst;
			xlnx,vaux14 = <0>;
			xlnx,vccpaux-alarm-lower = <0x1a17b0>;
			xlnx,vccaux-alarm-lower = <0x1ab3f0>;
			xlnx,vaux15 = <0>;
			compatible = "xlnx,xadc-wiz-3.3" , "xlnx,axi-xadc-1.00.a";
			xlnx,has-external-mux = <0>;
			xlnx,vccaux-alarm;
			xlnx,sampling-rate = <0x7fffffff>;
			xlnx,has-reset = <0>;
			xlnx,adc-conversion-rate = <1000>;
			xlnx,vccddro-alarm-lower = <0x124f80>;
			xlnx,enable-calibration-averaging;
			xlnx,has-user-temp-alarm = <1>;
			interrupt-parent = <&intc>;
			xlnx,has-ot-alarm = <1>;
			xlnx,has-convst = <0>;
			xlnx,single-channel-selection = "TEMPERATURE";
			xlnx,startup-channel-selection = "single_channel";
			xlnx,interface-selection = "Enable_AXI";
			xlnx,vccpaux-alarm-upper = <0x1b7740>;
			xlnx,vccaux-alarm-upper = <0x1cd6d0>;
			status = "okay";
			xlnx,sensor-offset-and-gain-calibration;
			xlnx,vccddro-alarm-upper = <0x1312d0>;
			xlnx,name = "xadc_wiz";
			xlnx,external-mux = "none";
			interrupts = < 0 58 4 >;
			xlnx,enable-vccddro-alarm;
			xlnx,enable-eoc;
			xlnx,enable-jtaglocked;
			xlnx,sim-file-name = "design";
			xlnx,enable-vccpint-alarm;
			xlnx,temperature-alarm-reset = <60>;
			xlnx,addr-width = <32>;
			clocks = <&clkc 15>;
			xlnx,alarm-limit-r10 = <21845>;
			xlnx,alarm-limit-r11 = <20753>;
			xlnx,alarm-limit-r12 = <39321>;
			xlnx,edk-iptype = "PERIPHERAL";
			xlnx,alarm-limit-r13 = <37355>;
			xlnx,sequencer-mode;
			xlnx,enable-jtagbusy;
			xlnx,alarm-limit-r14 = <27306>;
			xlnx,include-intr = <1>;
			xlnx,alarm-limit-r15 = <26214>;
			xlnx,fifo-depth = <7>;
			clock-names = "s_axi_aclk";
			xlnx,enable-vccpaux-alarm;
			xlnx,has-eoc = <1>;
			xlnx,temperature-alarm-ot-trigger = <125>;
			xlnx,has-channel = <1>;
			xlnx,enable-eos;
			xlnx,vccpint-alarm-lower = <0xe7ef0>;
			xlnx,vccint-alarm-lower = <0xecd10>;
			xlnx,has-dclk = <1>;
			xlnx,vbram-alarm-lower = <0xe7ef0>;
			xlnx,num-wave = <1>;
			xlnx,sequence-r0 = <256>;
			xlnx,has-jtagmodified = <0>;
			xlnx,sequence-r1 = <0>;
			xlnx,enable-drp;
			xlnx,sequence-r2 = <0>;
			xlnx,has-vccint-alarm = <1>;
			xlnx,channel-averaging = "None";
			xlnx,sequence-r3 = <0>;
			xlnx,has-axi4stream = <0>;
			xlnx,sequence-r4 = <0>;
			xlnx,sequence-r5 = <0>;
			xlnx,adc-offset-and-gain-calibration;
			xlnx,waveform-type = "CONSTANT";
			xlnx,sequence-r6 = <0>;
			xlnx,vccddro-volt = "1_2";
			xlnx,sequence-r7 = <0>;
			xlnx,has-vccddro-alarm = <1>;
			xlnx,alarm-limit-r0 = <46573>;
			xlnx,has-convstclk = <0>;
			xlnx,has-eos = <1>;
			xlnx,stimulus-freq = <1>;
			xlnx,single-channel-enable-calibration;
			xlnx,alarm-limit-r1 = <22500>;
			xlnx,component-name = "system_xadc_wiz_0";
			xlnx,external-muxaddr-enable = <0>;
		};
	};
};
